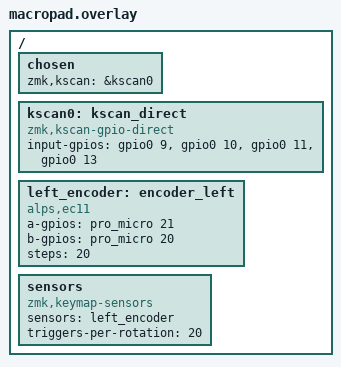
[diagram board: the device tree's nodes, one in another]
/ {
    chosen {
        zmk,kscan = &kscan0;
    };

    kscan0: kscan_direct {
        compatible = "zmk,kscan-gpio-direct";
        input-gpios = <&gpio0 9 GPIO_ACTIVE_HIGH>,
                      <&gpio0 10 GPIO_ACTIVE_HIGH>,
                      <&gpio0 11 GPIO_ACTIVE_HIGH>,
                      <&gpio0 13 GPIO_ACTIVE_HIGH>;
    };
};
     / { left_encoder: encoder_left {
        compatible = "alps,ec11";
        a-gpios = <&pro_micro 21 (GPIO_ACTIVE_HIGH | GPIO_PULL_UP)>;
        b-gpios = <&pro_micro 20 (GPIO_ACTIVE_HIGH | GPIO_PULL_UP)>;
        steps = <20>;
        status = "enabled";
    };
};
  &left_encoder {
    status = "okay";
    };

   / { sensors: sensors {
        compatible = "zmk,keymap-sensors";
        sensors = <&left_encoder>;
        triggers-per-rotation = <20>;
    };
};
